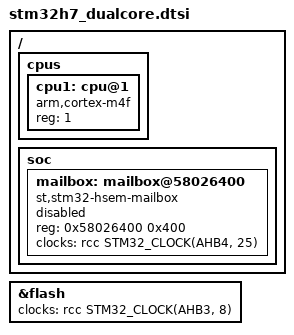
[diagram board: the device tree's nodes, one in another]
/*
 * Copyright (c) 2020 Moonkwun Jung
 *
 * SPDX-License-Identifier: Apache-2.0
 */

#include <st/h7/stm32h7.dtsi>

/ {
	cpus {
		cpu1: cpu@1 {
			device_type = "cpu";
			compatible = "arm,cortex-m4f";
			reg = <1>;
		};
	};

	soc {
		mailbox: mailbox@58026400 {
			compatible = "st,stm32-hsem-mailbox", "st,mbox-stm32-hsem";
			reg = <0x58026400 0x400>;
			clocks = <&rcc STM32_CLOCK(AHB4, 25)>;
			#mbox-cells = <1>;
			status = "disabled";
		};
	};
};

&flash {
	clocks = <&rcc STM32_CLOCK(AHB3, 8)>;
};
